# GD32H77x_78x register map
File version: 1.0
CPU: CM7 r1p2, little endian, MPU, FPU, 4 interrupt priority bits
Registers are 32-bit, read-write, reset 0x0 unless marked. A register's access mark holds for its fields unless they carry their own. Offsets are from the block's base; [hi:lo] are bit positions; {n}, {i} and the like mark numbered series; 'fields as' and 'values as' point back to an identical list.

## ESC — EtherCAT SubDevice Controller
Base 0x5F000000
0x00 TYPE 8-bit ro reset 0xBC — Type of EtherCAT controller
0x01 REVISION 8-bit ro — ESC Revision register
  [7:0] REVISION — Revision of EtherCAT controller
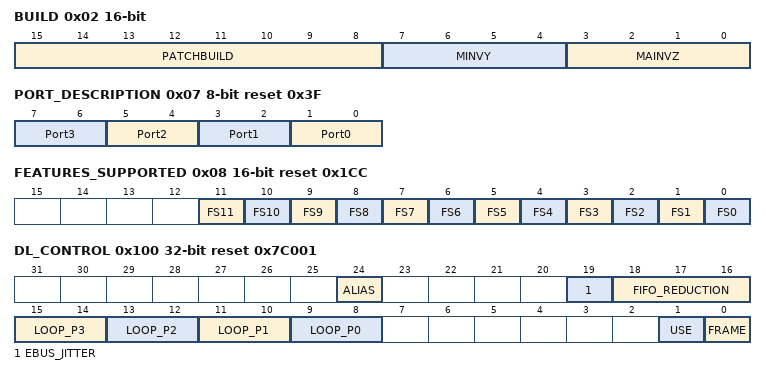
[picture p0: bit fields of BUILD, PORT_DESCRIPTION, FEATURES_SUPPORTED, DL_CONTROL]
0x02 BUILD 16-bit ro — ESC Build register
  [15:8] PATCHBUILD — patch level / development build
  [7:4] MINVY — minor version Y
  [3:0] MAINVZ — maintenance version Z
0x04 FMMUS 8-bit ro reset 0x8 — ESC FMMU numbers register
  [7:0] FMMU — Number of supported FMMU channels
0x05 SYNCMANAGERS 8-bit ro reset 0x8 — ESC SyncManagers numbers register
  [7:0] SM — Number of supported SyncManager entities
0x06 RAMSIZE 8-bit ro reset 0x8 — ESC RAM size register
  [7:0] RAMSIZE — Process Data RAM size in 8Kbyte
0x07 PORT_DESCRIPTION 8-bit ro reset 0x3F — ESC Port descriptor register
  [2n+1:2n] Port{n} (n=0..3) — Port {n} Configuration
0x08 FEATURES_SUPPORTED 16-bit ro reset 0x1CC — ESC Features supporter register
  [11] FS11 — Fixed FMMU / SyncManager configuration
  [10] FS10 — EtherCAT read/write command support
  [9] FS9 — EtherCAT LRW command support
  [8] FS8 — Enhanced DC SYNC Activation
  [7] FS7 — Separate Handling of FCS Errors
  [6] FS6 — Enhanced Link Detection MII
  [5] FS5 — Enhanced Link Detection EBUS
  [4] FS4 — Low Jitter EBUS
  [3] FS3 — Distributed Clocks width
  [2] FS2 — Distributed Clocks availability
  [1] FS1 — Unused register access
  [0] FS0 — FMMU Operation mode
0x10 STATION_ADDRESS 16-bit — ESC Configured station address register
  [15:0] CSAD — Configured Station Address
0x12 STATION_ALIAS 16-bit — ESC Configured station alias register
  [15:0] CSAL — Configured Station Alias
0x20 WRITE_ENABLE 8-bit
  [0] WEN — Write Enable
0x21 ESC_WRITE_PROTECTION 8-bit
  [0] WPR — Write Protection
0x30 ESC_WRITE_ENABLE 8-bit
  [0] EWEN — ESC Write Enable
0x31 WRITE_PROTECTION 8-bit — ESC Write protection register
  [0] EWPR — Write Protection
0x40 RESET_ECAT 8-bit — ECAT reset register
  [7:0] RESET_ECAT — ECAT Reset Sequence
0x41 RESET_PDI 8-bit — ESC Reset PDI register
  [7:0] RESET_PDI — PDI Reset Sequence
0x100 DL_CONTROL reset 0x7C001 — ESC DL control register
  [24] ALIAS — Station alias enable
  [19] EBUS_JITTER — EBUS Low Jitter
  [18:16] FIFO_REDUCTION — RX FIFO Size reduction
  [2n+9:2n+8] LOOP_P{n} (n=0..3) — Loop Port {n} configuration
  [1] USE — Temporary use of settings
  [0] FRAME — Forwarding rule for non-EtherCAT frames
0x108 PHYSICAL_OFFSET 16-bit — ESC Physical read / write offset register
  [15:0] RW_OFFSET — Read/Write Offset
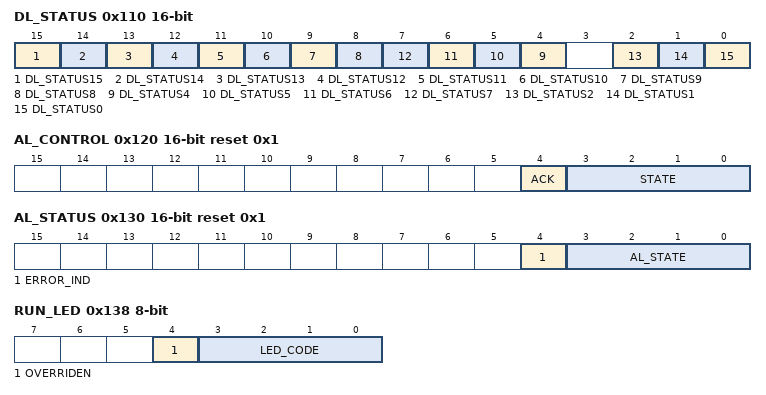
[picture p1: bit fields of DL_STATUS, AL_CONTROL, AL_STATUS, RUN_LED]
0x110 DL_STATUS 16-bit ro — ESC DL status register
  [15] DL_STATUS15 — Communication on Port 3
  [14] DL_STATUS14 — Loop Port 3
  [13] DL_STATUS13 — Communication on Port 2
  [12] DL_STATUS12 — Loop Port 2
  [11] DL_STATUS11 — Communication on Port 1
  [10] DL_STATUS10 — Loop Port 1
  [9] DL_STATUS9 — Communication on Port 0
  [8] DL_STATUS8 — Loop Port 0
  [n] DL_STATUS{n} (n=4..7) — Physical link on Port {n-4}
  [2] DL_STATUS2 — Enhanced Link detection
  [1] DL_STATUS1 — PDI Watchdog Status
  [0] DL_STATUS0 — PDI operational / EEPROM loaded correctly
0x120 AL_CONTROL 16-bit reset 0x1 — ESC AL control register
  [4] ACK — Error Ind Ack
  [3:0] STATE — Initiate State Transition
0x130 AL_STATUS 16-bit reset 0x1 — ESC AL status register
  [4] ERROR_IND — Error Indicator
  [3:0] AL_STATE — Actual State of the Device State Machine
0x134 AL_STATUS_CODE 16-bit — ESC AL status code register
0x138 RUN_LED 8-bit — ESC RUN LED override register
  [4] OVERRIDEN — Enable Override
  [3:0] LED_CODE — LED code for RUN LED
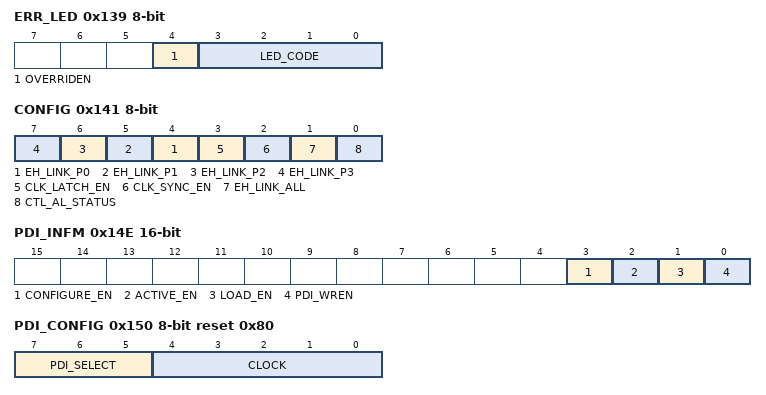
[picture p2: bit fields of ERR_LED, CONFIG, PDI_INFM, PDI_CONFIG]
0x139 ERR_LED 8-bit — ESC ERR LED override register
  [4] OVERRIDEN — Enable Override
  [3:0] LED_CODE
0x140 PDI_CONTROL 8-bit ro reset 0x80 — ESC PDI control register
  [7:0] PDI_CTL — Process data interface type
0x141 CONFIG 8-bit ro — ESC configuration register
  [n+4] EH_LINK_P{n} (n=0..3) — Enhanced Link port {n}
  [3] CLK_LATCH_EN — Distributed Clocks Latch In Unit
  [2] CLK_SYNC_EN — Distributed Clocks SYNC Out Unit
  [1] EH_LINK_ALL — Enhanced Link detection all ports
  [0] CTL_AL_STATUS — Device emulation (control of AL status)
0x14E PDI_INFM 16-bit ro — PDI information register
  [3] CONFIGURE_EN — PDI configuration invalid
  [2] ACTIVE_EN — PDI active
  [1] LOAD_EN — ESC configuration area loaded from EEPROM
  [0] PDI_WREN — PDI function acknowledge by write
0x150 PDI_CONFIG 8-bit ro reset 0x80 — ESC PDI configuration register
  [7:5] PDI_SELECT — On-chip bus selection
  [4:0] CLOCK — On-chip bus clock configuration
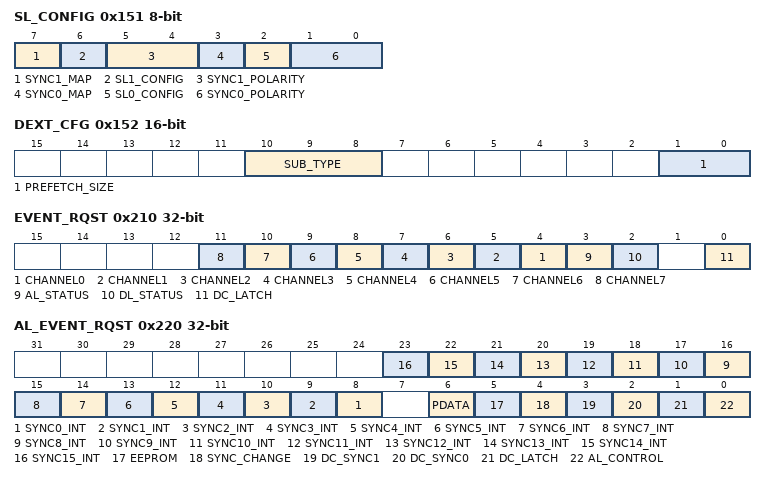
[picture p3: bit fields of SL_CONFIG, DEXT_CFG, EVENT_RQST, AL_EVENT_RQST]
0x151 SL_CONFIG 8-bit ro — ESC Sync / Latch configuration register
  [7] SYNC1_MAP — SYNC1 mapped to AL Event Request Register 0x0220[3]
  [6] SL1_CONFIG — SYNC1 / LATCH1 Configuration
  [5:4] SYNC1_POLARITY — SYNC1 Output Driver / Polarity
  [3] SYNC0_MAP — SYNC0 mapped to AL Event Request Register 0x0220[2]
  [2] SL0_CONFIG — SYNC0 / LATCH0 Configuration
  [1:0] SYNC0_POLARITY — SYNC0 Output Driver / Polarity
0x152 DEXT_CFG 16-bit — ESC PDI extended configuration register
  [10:8] SUB_TYPE — On-chip bus sub-type for AXI
  [1:0] PREFETCH_SIZE — Read prefetch size (in cycles of PDI width)
0x200 EVENT_MASK 16-bit — ESC Event mask register
  [15:0] EVENT_REQ — ECAT Event masking of the ECAT Event Request Events
0x204 PDI_AL_EVENT reset 0xFFFF0F — ESC PDI AL event register
  [31:0] AL_EVENT_REQ — AL Event masking of the AL Event Request register Events
0x210 EVENT_RQST ro — ESC Event request register
  [n+4] CHANNEL{n} (n=0..7) — Sync Channel {n} event pending
  [3] AL_STATUS — AL Status event
  [2] DL_STATUS — DL Status event
  [0] DC_LATCH — DC Latch event
0x220 AL_EVENT_RQST ro — ESC AL event request register
  [n+8] SYNC{n}_INT (n=0..15) — SyncManager {n} interrupt pending
  [6] PDATA — Watchdog Process Data
  [5] EEPROM — EEPROM Emulation
  [4] SYNC_CHANGE — SyncManager activation register changed
  [3] DC_SYNC1 — State of DC SYNC1
  [2] DC_SYNC0 — State of DC SYNC0
  [1] DC_LATCH — DC Latch event
  [0] AL_CONTROL — AL Control event
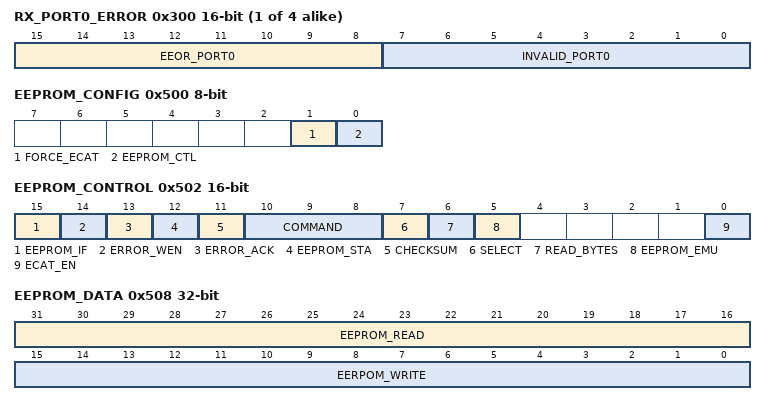
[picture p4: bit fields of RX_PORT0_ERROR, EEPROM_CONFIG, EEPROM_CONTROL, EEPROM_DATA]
{0x300+2i} RX_PORT{i}_ERROR 16-bit (i=0..3) — RX error port {i} register
  [15:8] EEOR_PORT{i} — Port {i} RX Error Counter
  [7:0] INVALID_PORT{i} — Port {i} Invalid Frame Counter
{0x308+i} FRX_PORT{i}_ERROR 8-bit (i=0..3) — Forwarded RX error port {i} register
  [7:0] F_ERROR_PORT{i} — Forwarded error counter of Port {i}
0x30C PU_ERROR 8-bit — ESC processing unit error register
  [7:0] PU_ERROR — ECAT Processing Unit error counter
0x30D PDI_ERROR 8-bit — ESC PDI error counter register
  [7:0] PDI_ERROR — PDI Error counter
{0x310+i} PORT{i}_LOST_LINK 8-bit (i=0..3) — ESC PORT{i} lost link register
  [7:0] LOST_LINK — Lost Link counter of Port {i}
0x400 WTG_DIVIDER 16-bit reset 0x9C2 — ESC Watchdog divider register
  [15:0] WATCHDOG_DIV — Watchdog divider
0x410 WTG_TIME 16-bit reset 0x3E8 — ESC Watchdog time PDI register
  [15:0] WATCHDOG_TIME — Watchdog Time PDI
0x420 WTG_TPD 16-bit reset 0x3E8 — ESC Watchdog time process data register
  [15:0] WATCHDOG_TPD — Watchdog Time Process Data
0x440 WTG_STATUS 16-bit — ESC Watchdog status process data register
  [0] WATCHDOG_STA — Watchdog Status of Process Data
0x442 WTG_CTR 8-bit — ESC Watchdog counter process data register
  [7:0] WATCHDOG_CPD — Watchdog Counter Process Data
0x443 WTG_CTR_PDI 8-bit — ESC Watchdog counter PDI register
  [7:0] WATCHDOG_PDIC — Watchdog PDI counter
0x500 EEPROM_CONFIG 8-bit — ESC EEPROM configuration register
  [1] FORCE_ECAT — Force ECAT access
  [0] EEPROM_CTL — EEPROM control is offered to PDI
0x501 EEPROM_ACCESS 8-bit — ESC EEPROM PDI access register
  [0] ACCESS_EEPROM — Access to EEPROM
0x502 EEPROM_CONTROL 16-bit — ESC EEPROM control / status register
  [15] EEPROM_IF — Busy
  [14] ERROR_WEN — Error Write Enable
  [13] ERROR_ACK — Error Acknowledge/Command
  [12] EEPROM_STA — EEPROM loading status
  [11] CHECKSUM — Checksum Error in ESC Configuration Area
  [10:8] COMMAND
  [7] SELECT — Selected EEPROM Algorithm
  [6] READ_BYTES — Supported number of EEPROM read bytes
  [5] EEPROM_EMU — EEPROM emulation
  [0] ECAT_EN — ECAT write enable
0x504 EEPROM_ADDR — ESC EEPROM address register
  [31:0] EEPROM_ADDR — EEPROM Address
0x508 EEPROM_DATA — ESC EEPROM data register
  [31:16] EEPROM_READ — EEPROM Read data
  [15:0] EERPOM_WRITE — EEPROM Write data or EEPROM Read data
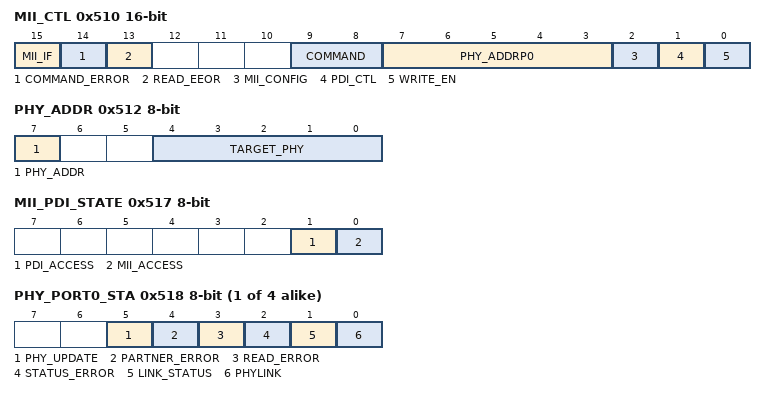
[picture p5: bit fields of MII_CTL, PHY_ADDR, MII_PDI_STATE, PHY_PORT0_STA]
0x510 MII_CTL 16-bit — ESC MII management control / status register
  [15] MII_IF — Busy
  [14] COMMAND_ERROR
  [13] READ_EEOR — Read error
  [9:8] COMMAND
  [7:3] PHY_ADDRP0 — PHY Address Port 0
  [2] MII_CONFIG — MI link detection and configuration
  [1] PDI_CTL — Management Interface can be controlled by PDI
  [0] WRITE_EN — Write Enable
0x512 PHY_ADDR 8-bit — ESC PHY Address Register
  [7] PHY_ADDR — Target PHY Address translation
  [4:0] TARGET_PHY — Target PHY Address
0x513 PHY_RADDR 8-bit — ESC PHY Register Address Register
  [4:0] PHY_RADDR — Address of PHY Register that shall be read/written
0x514 PHY_DATA 16-bit — ESC PHY Data Register
  [15:0] PHY_RWADDR — PHY Read/Write Data
0x516 MII_ECAT_STATE 8-bit — MII Management ECAT Access State Register
  [0] MII_ACCESS — Access to MII management
0x517 MII_PDI_STATE 8-bit — MII Management PDI Access State Register
  [1] PDI_ACCESS — Force PDI Access State
  [0] MII_ACCESS — Access to MII management
{0x518+i} PHY_PORT{i}_STA (i=0..3) 8-bit access per field — PHY Port X Status Register
  [5] PHY_UPDATE rw — PHY configuration updated
  [4] PARTNER_ERROR ro — Link partner error
  [3] READ_ERROR rw
  [2] STATUS_ERROR rw — Link status error
  [1] LINK_STATUS ro
  [0] PHYLINK ro — Physical link status
{0x600+0x10*i} FMMU{i}_LOGIC_ADDR (i=0..15) — Logical start address FMMU X register
  [31:0] LOGIC_ADDR — Logical start address within the EtherCAT Address Space
{0x604+0x10*i} FMMU{i}_LENGTH (i=0..15) 16-bit — Length FMMU X Register
  [15:0] LENGTH_FMMU — Offset from first logical FMMU byte to last FMMU byte + 1
{0x606+0x10*i} FMMU{i}_STRA_BIT (i=0..15) 8-bit — Start Bit FMMU X in Logical Address Space Register
  [2:0] START_BIT — Logical starting bit that shall be mapped
{0x607+0x10*i} FMMU{i}_STOP_BIT (i=0..15) 8-bit — Stop Bit FMMU X in Logical Address Space Register
  [2:0] STOP_BIT — Last logical bit that shall be mapped
{0x608+0x10*i} FMMU{i}_ADRR (i=0..15) 16-bit — Physical Start Address FMMU X Register
  [15:0] START_ADDR — Physical Start Address (mapped to logical Start address)
{0x60A+0x10*i} FMMU{i}_PSBIT (i=0..15) 8-bit — Physical Start Bit FMMU X Register
  [2:0] PSTART_BIT — Physical starting bit as target of logical start bit mapping
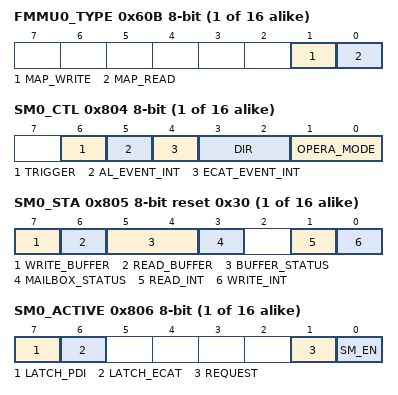
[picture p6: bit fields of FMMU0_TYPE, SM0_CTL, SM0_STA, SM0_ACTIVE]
0x60B FMMU{x}_TYPE (x=0,1,2,3,4,5,6,7,8,9,A,B,C,D,E,F; step 0x10) 8-bit — Type FMMU X Register
  [1] MAP_WRITE — 0=Ignore mapping for write, 1=Use mapping for write
  [0] MAP_READ — 0=Ignore mapping for read, 1=Use mapping for read
0x60C FMMU{x}_ACTIVE (x=0,1,2,3,4,5,6,7,8,9,A,B,C,D,E,F; step 0x10) 8-bit — Active FMMU X Register
  [0] ACTIVE_FMMU — 0=FMMU deactivated, 1=FMMU activated
0x800 SM{x}_ADRR (x=0,1,2,3,4,5,6,7,8,9,A,B,C,D,E,F; step 0x8) 16-bit — Physical Start Address SyncManager X Register
  [15:0] SMSTART_ADDR — First byte that will be handled by SyncManager
0x802 SM{x}_LENGTH (x=0,1,2,3,4,5,6,7,8,9,A,B,C,D,E,F; step 0x8) 16-bit — Length SyncManager X Register
  [15:0] LENGTH_SM — Number of bytes assigned to SyncManager
0x804 SM{x}_CTL (x=0,1,2,3,4,5,6,7,8,9,A,B,C,D,E,F; step 0x8) 8-bit — Control Register SyncManager X register
  [6] TRIGGER — Watchdog Trigger Enable
  [5] AL_EVENT_INT — Interrupt in AL Event Request Register
  [4] ECAT_EVENT_INT — Interrupt in ECAT Event Request Register
  [3:2] DIR — Direction
  [1:0] OPERA_MODE — Operation Mode
0x805 SM{x}_STA (x=0,1,2,3,4,5,6,7,8,9,A,B,C,D,E,F; step 0x8) 8-bit ro reset 0x30 — Status register SyncManager X register
  [7] WRITE_BUFFER — Write buffer in use
  [6] READ_BUFFER — Read buffer in use
  [5:4] BUFFER_STATUS — Buffered mode
  [3] MAILBOX_STATUS — Mailbox mode
  [1] READ_INT — Interrupt Read
  [0] WRITE_INT — Interrupt Write
0x806 SM{x}_ACTIVE (x=0,1,2,3,4,5,6,7,8,9,A,B,C,D,E,F; step 0x8) 8-bit — Activate SyncManager X Register
  [7] LATCH_PDI — Latch Event PDI
  [6] LATCH_ECAT — Latch Event ECAT
  [1] REQUEST — Repeat Request
  [0] SM_EN — SyncManager Enable
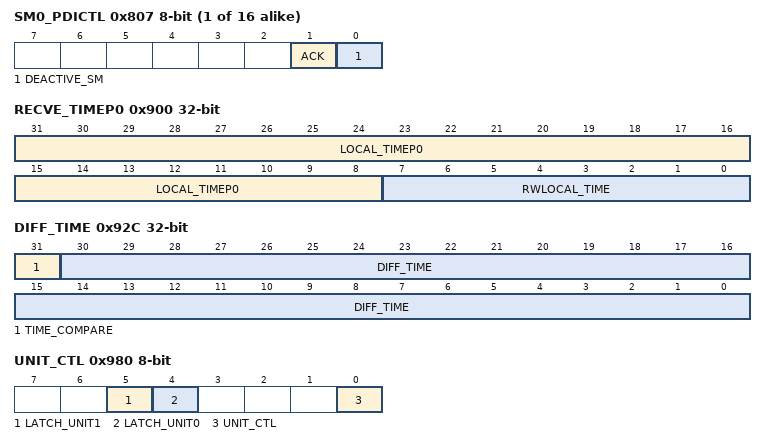
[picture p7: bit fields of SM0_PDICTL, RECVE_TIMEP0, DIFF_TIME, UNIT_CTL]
0x807 SM{x}_PDICTL (x=0,1,2,3,4,5,6,7,8,9,A,B,C,D,E,F; step 0x8) 8-bit — PDI Control SyncManager X Register
  [1] ACK — Repeat Ack
  [0] DEACTIVE_SM — Deactivate SyncManager
0x900 RECVE_TIMEP0 ro — ESC Receive Time Port 0 Register
  [31:8] LOCAL_TIMEP0 — Local time at the beginning of the last receive frame
  [7:0] RWLOCAL_TIME — Local time latched on write/read
0x904 RECVE_TIMEP1 ro — ESC Receive Time Port 1 Register
  [31:0] LOCAL_TIMEP1 — Local time at the beginning of a frame received at port 1
0x908 RECVE_TIMEP2 ro — ESC Receive Time Port 2 Register
  [31:0] LOCAL_TIMEP2 — Local time at the beginning of a frame received at port 2
0x910 SYS_TIME_L wo — ESC System Time Register
  [31:0] WRITE_ACCESS
0x914 SYS_TIME_H ro — ESC System Time Register
  [31:0] READ_ACCESS — ECAT read access
0x918 RCVTIME ro — ESC Receive Time ECAT Processing Unit Register
  [31:0] RECVE_TIME — Local time at the beginning of a frame at ECAT Processing Unit
0x920 OFFSET_TIME_L — ESC System Time Offset Register
  [31:0] OFFSET_TIME — Difference between local time and System Time
0x924 OFFSET_TIME_H — ESC System Time Offset Register
  [31:0] OFFSET_TIME — Difference between local time and System Time
0x928 DELAY_TIME — ESC System Time Delay Register
  [31:0] DELAY_TIME — Delay between Reference Clock and the ESC
0x92C DIFF_TIME ro — ESC System Time Difference Register
  [31] TIME_COMPARE — 0 = Local less than Received, 1 = Local greater than Received
  [30:0] DIFF_TIME — Mean difference between local and received System Time
0x930 COUNT_START 16-bit reset 0x1000 — ESC Speed Counter Start Register
  [14:0] BWIDTH — Bandwidth for adjustment of local System Time
0x932 COUNT_DIFF 16-bit ro — ESC Speed Counter Diff Register
  [15:0] DIFF_CLOCK — Representation of the deviation between local clock period and Reference Clock s clock period
0x934 TIME_DIFF 8-bit reset 0x4 — ESC System Time Difference Filter Depth Register
  [3:0] FILTER_DEPTH — Filter depth for averaging the received System Time deviation
0x935 SPEED_COUNT 8-bit reset 0x12 — ESC Speed Counter Filter Depth Register
  [3:0] FILTER_DEPTH — Filter depth for averaging the clock period deviation
0x980 UNIT_CTL 8-bit — ESC Cyclic Unit Control Register
  [5] LATCH_UNIT1 — Latch In unit 1
  [4] LATCH_UNIT0 — Latch In unit 0
  [0] UNIT_CTL — Cyclic Unit and SYNC0 out unit control
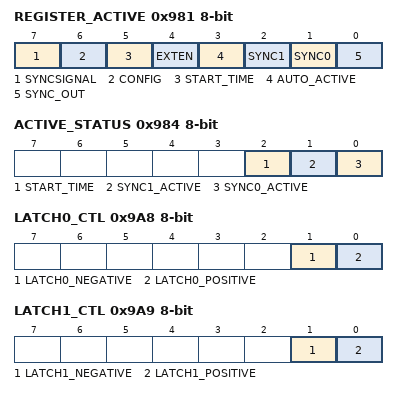
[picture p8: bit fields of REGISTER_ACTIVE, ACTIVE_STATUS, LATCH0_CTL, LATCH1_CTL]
0x981 REGISTER_ACTIVE 8-bit — ESC Register Activation Register
  [7] SYNCSIGNAL — SyncSignal debug pulse
  [6] CONFIG — Near future configuration
  [5] START_TIME — Start Time plausibility check
  [4] EXTEN — Extension of Start Time Cyclic Operation
  [3] AUTO_ACTIVE — Auto-activation by writing Start Time Cyclic Operation
  [2] SYNC1 — SYNC1 generation
  [1] SYNC0 — SYNC0 generation
  [0] SYNC_OUT — Sync Out Unit activation
0x982 PLEN_SM 16-bit ro — ESC Pulse Length of Sync Signals Register
  [15:0] PLEN_SM — Pulse length of SyncSignals
0x984 ACTIVE_STATUS 8-bit ro — ESC Activation Status Register
  [2] START_TIME — Start Time Cyclic Operation plausibility check result when Sync Out Unit was activated
  [1] SYNC1_ACTIVE — SYNC1 activation state
  [0] SYNC0_ACTIVE — SYNC0 activation state
0x98E SYNC0_STATUS 8-bit — ESC SYNC0 Status Register
  [0] SYNC0_STATE — SYNC0 state for Acknowledge mode
0x98F SYNC1_STATUS 8-bit — ESC SYNC1 Status Register
  [0] SYNC1_STATE — SYNC1 state for Acknowledge mode
0x990 START_TIME_L — ESC Start Time Cyclic Operation Register
  [31:0] START_TIME — Write: Start time (System time) of cyclic operation in ns, Read: System time of next SYNC0 pulse in ns
0x994 START_TIME_H — ESC Start Time Cyclic Operation Register
  fields as START_TIME_L
0x998 NEXT_SYNC1_L ro — ESC Next SYNC1 Pulse Register
  [31:0] NEXT_SYNC1 — System time of next SYNC1 pulse in ns
0x99C NEXT_SYNC1_H ro — ESC Next SYNC1 Pulse Register
  [31:0] NEXT_SYNC1 — System time of next SYNC1 pulse in ns
0x9A0 SYNC0_CYCLE — ESC SYNC0 Cycle Time Register
  [31:0] SYNC0_CYCLE — Time between two consecutive SYNC0 pulses in ns
0x9A4 SYNC1_CYCLE — ESC SYNC1 Cycle Time Register
  [31:0] SYNC1_CYCLE — Time between SYNC0 pulse and SYNC1 pulse in ns
0x9A8 LATCH0_CTL 8-bit — ESC Latch0 Control Register
  [1] LATCH0_NEGATIVE — Latch0 negative edge
  [0] LATCH0_POSITIVE — Latch0 positive edge
0x9A9 LATCH1_CTL 8-bit — ESC Latch1 Control Register
  [1] LATCH1_NEGATIVE — Latch1 negative edge
  [0] LATCH1_POSITIVE — Latch1 positive edge
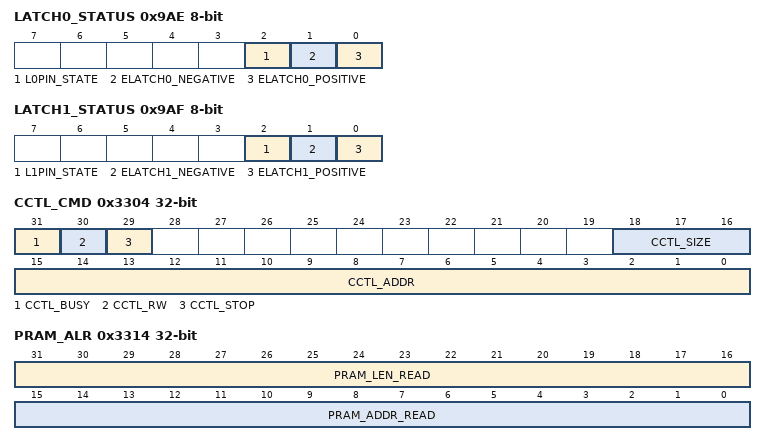
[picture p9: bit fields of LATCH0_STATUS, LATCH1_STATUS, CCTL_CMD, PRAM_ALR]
0x9AE LATCH0_STATUS 8-bit ro — ESC Latch0 Status Register
  [2] L0PIN_STATE — Latch0 pin state
  [1] ELATCH0_NEGATIVE — Event Latch0 negative edge
  [0] ELATCH0_POSITIVE — Event Latch0 positive edge
0x9AF LATCH1_STATUS 8-bit ro — ESC Latch1 Status Register
  [2] L1PIN_STATE — Latch1 pin state
  [1] ELATCH1_NEGATIVE — Event Latch1 negative edge
  [0] ELATCH1_POSITIVE — Event Latch1 positive edge
0x9B0 LATCH0_POSITIVE_L — ESC Latch0 Time Positive Edge Register
  [31:0] L0_POSITIVE — System time at the positive edge of the Latch0 signal
0x9B4 LATCH0_POSITIVE_H — ESC Latch0 Time Positive Edge Register
  fields as LATCH0_POSITIVE_L
0x9B8 LATCH0_NEGATIVE_L — ESC Latch0 Time Negative Edge Register
  [31:0] L0_NEGATIVE — System time at the negative edge of the Latch0 signal
0x9BC LATCH0_NEGATIVE_H — ESC Latch0 Time Negative Edge Register
  fields as LATCH0_NEGATIVE_L
0x9C0 LATCH1_POSITIVE_L — ESC Latch1 Time Positive Edge Register
  [31:0] L1_POSITIVE — System time at the positive edge of the Latch1 signal
0x9C4 LATCH1_POSITIVE_H — ESC Latch1 Time Positive Edge Register
  fields as LATCH1_POSITIVE_L
0x9C8 LATCH1_NEGATIVE_L — ESC Latch1 time negative edge register
  [31:0] L1_NEGATIVE — System time at the negative edge of the Latch1 signal
0x9CC LATCH1_NEGATIVE_H — ESC Latch1 time negative edge register
  fields as LATCH1_NEGATIVE_L
0x9F0 EVENT_TIME ro — ESC Buffer Change Event Time Register
  [31:0] EVENT_TIME — Local time at the beginning of the frame causing an ECAT event
0x9F8 PDI_SEVENT_TIME ro — ESC PDI Buffer Start Event Time Register
  [31:0] PDI_SEVENT_TIME — Local time when a SyncManager asserts a PDI buffer start event
0x9FC PDI_CEVENT_TIME ro — ESC PDI Buffer Change Event Time Register
  [31:0] PDI_CEVENT_TIME — Local time when a SyncManager asserts a PDI buffer change event
0xE00 PRODUCT_ID_L ro — ESC Product ID Register
  [31:0] PRODUCT_ID
0xE04 PRODUCT_ID_H ro — ESC Product ID Register
  [31:0] PRODUCT_ID
0xE08 VENDOR_ID_L ro — ESC Vendor ID Register
  [31:0] VENDOR_ID
0xE0C VENDOR_ID_H ro — ESC Vendor ID Register
  [31:0] VENDOR_ID
0xF00 DIG_DATA — ESC Digital I/O Output Data Register
  [31:0] OUTPUT_DATA
0xF10 GP_OUTPUT_L — ESC General Purpose Outputs Register
  [31:0] GP_OUTPUT — General Purpose Output Data
0xF14 GP_OUTPUT_H — ESC General Purpose Outputs Register
  [31:0] GP_OUTPUT — General Purpose Output Data
0xF18 GP_INPUTS_L ro — ESC General Purpose Inputs Register
  [31:0] GP_INPUT — General Purpose Input Data
0xF1C GP_INPUTS_H ro — ESC General Purpose Inputs Register
  [31:0] GP_INPUT — General Purpose Input Data
0x1000 PDI_DATA — ESC PDI Input Data Register
  [31:0] INPUT_DATA
0x3300 CCTL_DATA — ESC CCTL data register
  [31:0] CCTL_DATA — ESC CCTL data
0x3304 CCTL_CMD — ESC CCTL command register
  [31] CCTL_BUSY — CCTL Busy. There is no effect if the bit is written to 0
  [30] CCTL_RW — Read or write selection
  [29] CCTL_STOP — Stop read or write operation. There is no effect if the bit is written to 0.
  [18:16] CCTL_SIZE — This field specifies the size of the register that is about to be read or write. (in byte). Only 1, 2 and 4 are valid, other values are invalid.
  [15:0] CCTL_ADDR — This field specifies the address of ESC registers that will be accessed.
0x3310 PRAM_FIFO_DR ro — ESC PRAM FIFO data read register
  [31:0] PRAM_FIFO_DATA_READ — Data read from ESC PRAM.
0x3314 PRAM_ALR — ESC PRAM address and length read register
  [31:16] PRAM_LEN_READ — Data length read from ESC PRAM in bytes. This field is decremented as data is read into the FIFO.
  [15:0] PRAM_ADDR_READ — ESC PRAM data read address. This field is incremented as data is read into the FIFO.
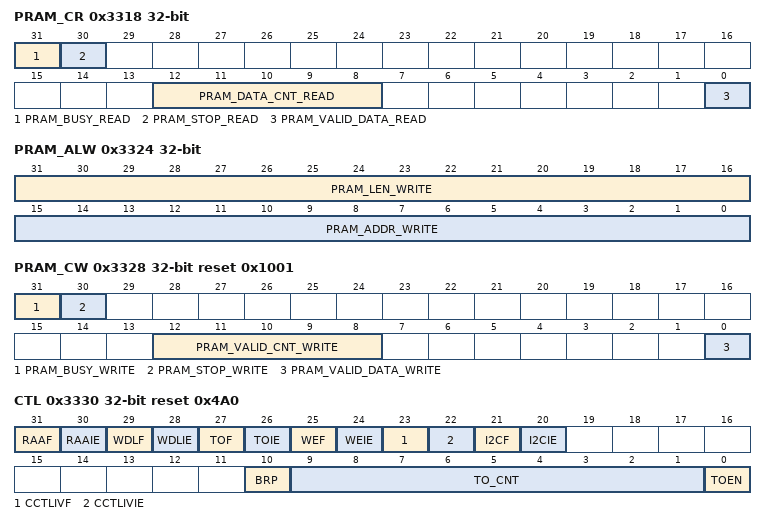
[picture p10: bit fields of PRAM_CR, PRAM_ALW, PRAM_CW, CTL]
0x3318 PRAM_CR access per field — ESC PRAM command read register
  [31] PRAM_BUSY_READ rw — Whether the PRAM is being read. There is no effect if the bit is written to 0
  [30] PRAM_STOP_READ rw — Stop PRAM read operation. There is no effect if the bit is written to zero
  [12:8] PRAM_DATA_CNT_READ ro — PRAM data read valid count
  [0] PRAM_VALID_DATA_READ ro
0x3320 PRAM_FIFO_DW wo — ESC PRAM FIFO data write register
  [31:0] PRAM_FIFO_DATA_WRITE — Data write to ESC PRAM.
0x3324 PRAM_ALW — ESC PRAM address and length write register
  [31:16] PRAM_LEN_WRITE — Data length written to ESC PRAM in bytes. This field is decremented as data is written into the FIFO.
  [15:0] PRAM_ADDR_WRITE — ESC PRAM data write address. This field is incremented as data is read from the FIFO.
0x3328 PRAM_CW access per field reset 0x1001 — ESC PRAM command write register
  [31] PRAM_BUSY_WRITE rw — Whether the PRAM is being written. There is no effect if the bit is written to zero
  [30] PRAM_STOP_WRITE rw — Stop PRAM write operation. There is no effect if the bit is written to zero
  [12:8] PRAM_VALID_CNT_WRITE ro — PRAM data write valid count
  [0] PRAM_VALID_DATA_WRITE ro
0x3330 CTL reset 0x4A0 — ESC Control register
  [31] RAAF — Reserved address access flag. This flag will be triggered when the access address is a reserved address segment. This flag can be cleared by writing 1.
  [30] RAAIE — Reserved address access interrupt enable
  [29] WDLF — Write data lost flag
  [28] WDLIE — Write data lost interrupt enable
  [27] TOF — Time out flag, when single transmission time exceeds the programmed value, this flag will be triggered. This flag can be cleared by writing 1.
  [26] TOIE — Timer out interrupt enable
  [25] WEF — write error flag. when BRP disable, AHB write operation will cause current OPB transmission error when the busy bit is high, this flag will be triggered. This flag can be cleared by writing 1.
  [24] WEIE — Write error interrupt enable.
  [23] CCTLIVF — CCTL_SIZE and CCTL_ADDR illegal value flag
  [22] CCTLIVIE — CCTL_SIZE and CCTL_ADDR Illegal value interrupt enable.
  [21] I2CF — Internal I2C communication error flag.
  [20] I2CIE — Internal I2C overrun interrupt enable.
  [10] BRP — When busy bit is high, prevent register change
  [9:1] TO_CNT — Time Out counter
  [0] TOEN — Time Out enable
